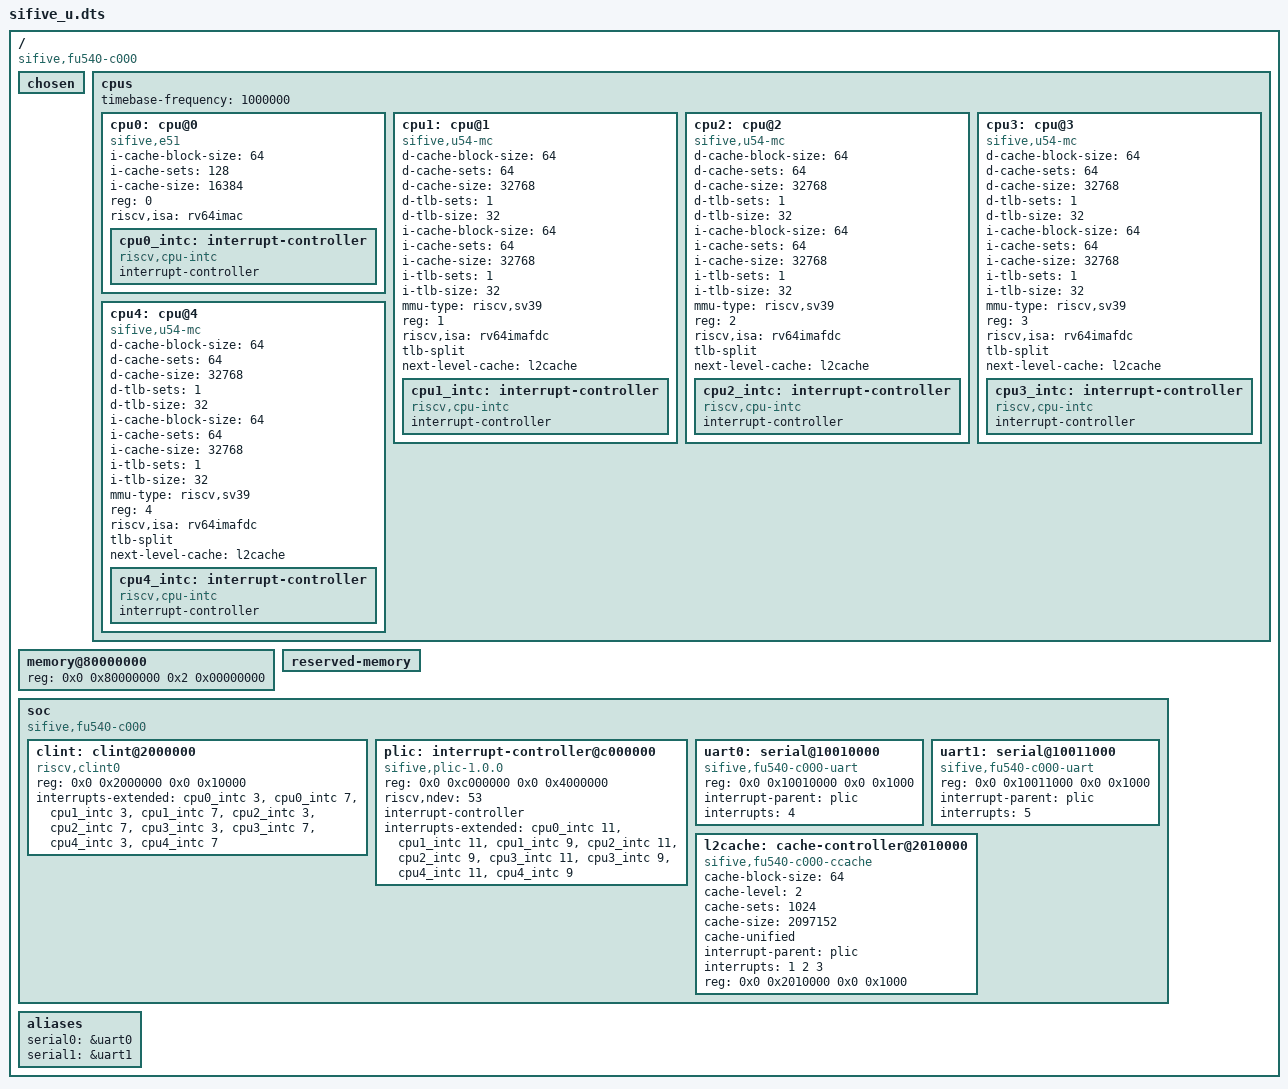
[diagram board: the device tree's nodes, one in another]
// SPDX-License-Identifier: (GPL-2.0 OR MIT)
/* Copyright (c) 2018-2019 SiFive, Inc */

/* MODIFIED */

/dts-v1/;

/ {
	#address-cells = <2>;
	#size-cells = <2>;
	compatible = "sifive,fu540-c000", "sifive,fu540";

	chosen {
	};

	cpus {
		#address-cells = <1>;
		#size-cells = <0>;
		timebase-frequency = <1000000>;

		cpu0: cpu@0 {
			compatible = "sifive,e51", "sifive,rocket0", "riscv";
			device_type = "cpu";
			i-cache-block-size = <64>;
			i-cache-sets = <128>;
			i-cache-size = <16384>;
			reg = <0>;
			riscv,isa = "rv64imac";

			cpu0_intc: interrupt-controller {
				#interrupt-cells = <1>;
				compatible = "riscv,cpu-intc";
				interrupt-controller;
			};
		};

		cpu1: cpu@1 {
			compatible = "sifive,u54-mc", "sifive,rocket0", "riscv";
			d-cache-block-size = <64>;
			d-cache-sets = <64>;
			d-cache-size = <32768>;
			d-tlb-sets = <1>;
			d-tlb-size = <32>;
			device_type = "cpu";
			i-cache-block-size = <64>;
			i-cache-sets = <64>;
			i-cache-size = <32768>;
			i-tlb-sets = <1>;
			i-tlb-size = <32>;
			mmu-type = "riscv,sv39";
			reg = <1>;
			riscv,isa = "rv64imafdc";
			tlb-split;
			next-level-cache = <&l2cache>;

			cpu1_intc: interrupt-controller {
				#interrupt-cells = <1>;
				compatible = "riscv,cpu-intc";
				interrupt-controller;
			};
		};

		cpu2: cpu@2 {
			compatible = "sifive,u54-mc", "sifive,rocket0", "riscv";
			d-cache-block-size = <64>;
			d-cache-sets = <64>;
			d-cache-size = <32768>;
			d-tlb-sets = <1>;
			d-tlb-size = <32>;
			device_type = "cpu";
			i-cache-block-size = <64>;
			i-cache-sets = <64>;
			i-cache-size = <32768>;
			i-tlb-sets = <1>;
			i-tlb-size = <32>;
			mmu-type = "riscv,sv39";
			reg = <2>;
			riscv,isa = "rv64imafdc";
			tlb-split;
			next-level-cache = <&l2cache>;

			cpu2_intc: interrupt-controller {
				#interrupt-cells = <1>;
				compatible = "riscv,cpu-intc";
				interrupt-controller;
			};
		};

		cpu3: cpu@3 {
			compatible = "sifive,u54-mc", "sifive,rocket0", "riscv";
			d-cache-block-size = <64>;
			d-cache-sets = <64>;
			d-cache-size = <32768>;
			d-tlb-sets = <1>;
			d-tlb-size = <32>;
			device_type = "cpu";
			i-cache-block-size = <64>;
			i-cache-sets = <64>;
			i-cache-size = <32768>;
			i-tlb-sets = <1>;
			i-tlb-size = <32>;
			mmu-type = "riscv,sv39";
			reg = <3>;
			riscv,isa = "rv64imafdc";
			tlb-split;
			next-level-cache = <&l2cache>;

			cpu3_intc: interrupt-controller {
				#interrupt-cells = <1>;
				compatible = "riscv,cpu-intc";
				interrupt-controller;
			};
		};

		cpu4: cpu@4 {
			compatible = "sifive,u54-mc", "sifive,rocket0", "riscv";
			d-cache-block-size = <64>;
			d-cache-sets = <64>;
			d-cache-size = <32768>;
			d-tlb-sets = <1>;
			d-tlb-size = <32>;
			device_type = "cpu";
			i-cache-block-size = <64>;
			i-cache-sets = <64>;
			i-cache-size = <32768>;
			i-tlb-sets = <1>;
			i-tlb-size = <32>;
			mmu-type = "riscv,sv39";
			reg = <4>;
			riscv,isa = "rv64imafdc";
			tlb-split;
			next-level-cache = <&l2cache>;

			cpu4_intc: interrupt-controller {
				#interrupt-cells = <1>;
				compatible = "riscv,cpu-intc";
				interrupt-controller;
			};
		};
	};

	memory@80000000 {
		device_type = "memory";
		reg = <0x0 0x80000000 0x2 0x00000000>;
	};

	reserved-memory {
		#address-cells = <2>;
		#size-cells = <2>;
		ranges;

    /* QEmu patches this DTS and adds following on its own:
     *
     * mmode_resv0@80000000 {
     *   no-map;
     *   reg = <0x00 0x80000000 0x00 0x40000>;
     * };
     */
    /*
     * opensbi@80000000 {
     *   reg = <0x0 0x80000000 0x0 0x40000>;
     * };
     */
	};

	soc {
		#address-cells = <2>;
		#size-cells = <2>;
		compatible = "sifive,fu540-c000", "sifive,fu540", "simple-bus";
		ranges;

		clint: clint@2000000 {
			compatible = "riscv,clint0";
			reg = <0x0 0x2000000 0x0 0x10000>;
			interrupts-extended = <&cpu0_intc 3 &cpu0_intc 7>,
				<&cpu1_intc 3 &cpu1_intc 7>,
				<&cpu2_intc 3 &cpu2_intc 7>,
				<&cpu3_intc 3 &cpu3_intc 7>,
				<&cpu4_intc 3 &cpu4_intc 7>;
		};

		plic: interrupt-controller@c000000 {
			#interrupt-cells = <1>;
			compatible = "sifive,plic-1.0.0";
			reg = <0x0 0xc000000 0x0 0x4000000>;
			riscv,ndev = <53>;
			interrupt-controller;
			interrupts-extended = <&cpu0_intc 11>,
				<&cpu1_intc 11 &cpu1_intc 9>,
				<&cpu2_intc 11 &cpu2_intc 9>,
				<&cpu3_intc 11 &cpu3_intc 9>,
				<&cpu4_intc 11 &cpu4_intc 9>;
		};

		uart0: serial@10010000 {
			compatible = "sifive,fu540-c000-uart", "sifive,uart0";
			reg = <0x0 0x10010000 0x0 0x1000>;
			interrupt-parent = <&plic>;
			interrupts = <4>;
		};

		uart1: serial@10011000 {
			compatible = "sifive,fu540-c000-uart", "sifive,uart0";
			reg = <0x0 0x10011000 0x0 0x1000>;
			interrupt-parent = <&plic>;
			interrupts = <5>;
		};

		l2cache: cache-controller@2010000 {
			compatible = "sifive,fu540-c000-ccache", "cache";
			cache-block-size = <64>;
			cache-level = <2>;
			cache-sets = <1024>;
			cache-size = <2097152>;
			cache-unified;
			interrupt-parent = <&plic>;
			interrupts = <1 2 3>;
			reg = <0x0 0x2010000 0x0 0x1000>;
		};
	};

	aliases {
		serial0 = &uart0;
		serial1 = &uart1;
	};
};

